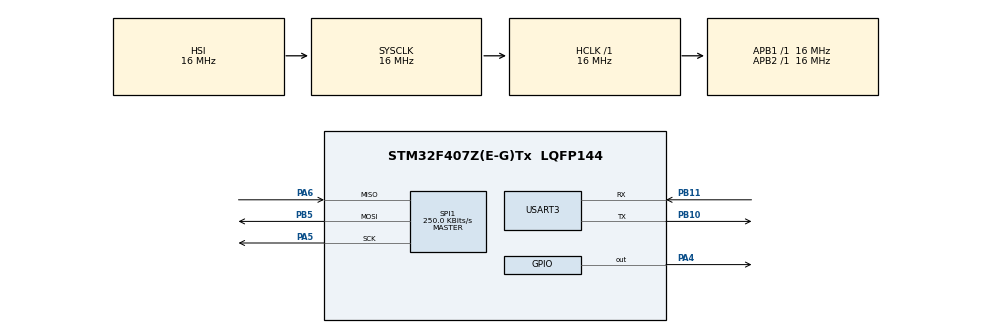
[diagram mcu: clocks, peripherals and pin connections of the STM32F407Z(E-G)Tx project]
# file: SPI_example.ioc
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FREERTOS.Tasks01=defaultTask,0,128,StartDefaultTask,Default,NULL
Mcu.Family=STM32F4
Mcu.Name=STM32F407Z(E-G)Tx
Mcu.Package=LQFP144
NVIC.PriorityGroup=NVIC_PRIORITYGROUP_4
PA4.Signal=GPIO_Output
PA5.Mode=Full_Duplex_Master
PA5.Signal=SPI1_SCK
PA6.Mode=Full_Duplex_Master
PA6.Signal=SPI1_MISO
PB10.Mode=Asynchronous
PB10.Signal=USART3_TX
PB11.Mode=Asynchronous
PB11.Signal=USART3_RX
PB5.Mode=Full_Duplex_Master
PB5.Signal=SPI1_MOSI
ProjectManager.HeapSize=0x200
ProjectManager.StackSize=0x400
ProjectManager.TargetToolchain=TrueSTUDIO
RCC.AHBFreq_Value=16000000
RCC.APB1Freq_Value=16000000
RCC.APB2Freq_Value=16000000
RCC.CortexFreq_Value=16000000
RCC.HSE_VALUE=25000000
RCC.HSI_VALUE=16000000
RCC.LSE_VALUE=32768
RCC.SYSCLKFreq_VALUE=16000000
RCC.VCOOutputFreq_Value=192000000
SPI1.BaudRatePrescaler=SPI_BAUDRATEPRESCALER_64
SPI1.CalculateBaudRate=250.0 KBits/s
SPI1.Direction=SPI_DIRECTION_2LINES
SPI1.Mode=SPI_MODE_MASTER
SPI1.VirtualType=VM_MASTER
USART3.VirtualMode=VM_ASYNC
VP_FREERTOS_VS_ENABLE.Mode=Enabled
board=custom

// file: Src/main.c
/**
  ******************************************************************************
  * @file           : main.c
  * @brief          : Main program body
  ******************************************************************************
  * This notice applies to any and all portions of this file
  * that are not between comment pairs USER CODE BEGIN and
  * USER CODE END. Other portions of this file, whether
  * inserted by the user or by software development tools
  * are owned by their respective copyright owners.
  *
  * Copyright (c) 2018 STMicroelectronics International N.V.
  * All rights reserved.
  *
  * Redistribution and use in source and binary forms, with or without
  * modification, are permitted, provided that the following conditions are met:
  *
  * 1. Redistribution of source code must retain the above copyright notice,
  *    this list of conditions and the following disclaimer.
  * 2. Redistributions in binary form must reproduce the above copyright notice,
  *    this list of conditions and the following disclaimer in the documentation
  *    and/or other materials provided with the distribution.
  * 3. Neither the name of STMicroelectronics nor the names of other
  *    contributors to this software may be used to endorse or promote products
  *    derived from this software without specific written permission.
  * 4. This software, including modifications and/or derivative works of this
  *    software, must execute solely and exclusively on microcontroller or
  *    microprocessor devices manufactured by or for STMicroelectronics.
  * 5. Redistribution and use of this software other than as permitted under
  *    this license is void and will automatically terminate your rights under
  *    this license.
  *
  * THIS SOFTWARE IS PROVIDED BY STMICROELECTRONICS AND CONTRIBUTORS "AS IS"
  * AND ANY EXPRESS, IMPLIED OR STATUTORY WARRANTIES, INCLUDING, BUT NOT
  * LIMITED TO, THE IMPLIED WARRANTIES OF MERCHANTABILITY, FITNESS FOR A
  * PARTICULAR PURPOSE AND NON-INFRINGEMENT OF THIRD PARTY INTELLECTUAL PROPERTY
  * RIGHTS ARE DISCLAIMED TO THE FULLEST EXTENT PERMITTED BY LAW. IN NO EVENT
  * SHALL STMICROELECTRONICS OR CONTRIBUTORS BE LIABLE FOR ANY DIRECT, INDIRECT,
  * INCIDENTAL, SPECIAL, EXEMPLARY, OR CONSEQUENTIAL DAMAGES (INCLUDING, BUT NOT
  * LIMITED TO, PROCUREMENT OF SUBSTITUTE GOODS OR SERVICES; LOSS OF USE, DATA,
  * OR PROFITS; OR BUSINESS INTERRUPTION) HOWEVER CAUSED AND ON ANY THEORY OF
  * LIABILITY, WHETHER IN CONTRACT, STRICT LIABILITY, OR TORT (INCLUDING
  * NEGLIGENCE OR OTHERWISE) ARISING IN ANY WAY OUT OF THE USE OF THIS SOFTWARE,
  * EVEN IF ADVISED OF THE POSSIBILITY OF SUCH DAMAGE.
  *
  ******************************************************************************
  */
#include "main.h"
#include "stm32f4xx_hal.h"
#include "cmsis_os.h"

/* USER CODE BEGIN Includes */
uint8_t spiData[2];
/* USER CODE END Includes */

SPI_HandleTypeDef hspi1;

UART_HandleTypeDef huart3;

osThreadId defaultTaskHandle;

/* USER CODE BEGIN PV */
/* Private variables ---------------------------------------------------------*/

/* USER CODE END PV */

void SystemClock_Config(void);
static void MX_GPIO_Init(void);
static void MX_SPI1_Init(void);
static void MX_USART3_UART_Init(void);
void StartDefaultTask(void const * argument);

/* USER CODE BEGIN PFP */
/* Private function prototypes -----------------------------------------------*/

/* USER CODE END PFP */

int main(void)
{

  /* MCU Configuration----------------------------------------------------------*/

  /* Reset of all peripherals, Initializes the Flash interface and the Systick. */
  HAL_Init();

  /* Configure the system clock */
  SystemClock_Config();

  /* Initialize all configured peripherals */
  MX_GPIO_Init();
  MX_SPI1_Init();
  MX_USART3_UART_Init();

  /* Create the thread(s) */
  /* definition and creation of defaultTask */
  osThreadDef(defaultTask, StartDefaultTask, osPriorityNormal, 0, 128);
  defaultTaskHandle = osThreadCreate(osThread(defaultTask), NULL);

  /* Start scheduler */
  osKernelStart();

  /* We should never get here as control is now taken by the scheduler */

  /* Infinite loop */
  /* USER CODE BEGIN WHILE */
  HAL_GPIO_WritePin(GPIOA, GPIO_PIN_4, GPIO_PIN_SET);
  while (1)
  {

  /* USER CODE END WHILE */

  }

}

void SystemClock_Config(void)
{

  RCC_OscInitTypeDef RCC_OscInitStruct;
  RCC_ClkInitTypeDef RCC_ClkInitStruct;

    /**Configure the main internal regulator output voltage
    */
  __HAL_RCC_PWR_CLK_ENABLE();

  __HAL_PWR_VOLTAGESCALING_CONFIG(PWR_REGULATOR_VOLTAGE_SCALE1);

    /**Initializes the CPU, AHB and APB busses clocks
    */
  RCC_OscInitStruct.OscillatorType = RCC_OSCILLATORTYPE_HSI;
  RCC_OscInitStruct.HSIState = RCC_HSI_ON;
  RCC_OscInitStruct.HSICalibrationValue = 16;
  RCC_OscInitStruct.PLL.PLLState = RCC_PLL_NONE;
  if (HAL_RCC_OscConfig(&RCC_OscInitStruct) != HAL_OK)
  {
    _Error_Handler(__FILE__, __LINE__);
  }

    /**Initializes the CPU, AHB and APB busses clocks
    */
  RCC_ClkInitStruct.ClockType = RCC_CLOCKTYPE_HCLK|RCC_CLOCKTYPE_SYSCLK
                              |RCC_CLOCKTYPE_PCLK1|RCC_CLOCKTYPE_PCLK2;
  RCC_ClkInitStruct.SYSCLKSource = RCC_SYSCLKSOURCE_HSI;
  RCC_ClkInitStruct.AHBCLKDivider = RCC_SYSCLK_DIV1;
  RCC_ClkInitStruct.APB1CLKDivider = RCC_HCLK_DIV1;
  RCC_ClkInitStruct.APB2CLKDivider = RCC_HCLK_DIV1;

  if (HAL_RCC_ClockConfig(&RCC_ClkInitStruct, FLASH_LATENCY_0) != HAL_OK)
  {
    _Error_Handler(__FILE__, __LINE__);
  }

    /**Configure the Systick interrupt time
    */
  HAL_SYSTICK_Config(HAL_RCC_GetHCLKFreq()/1000);

    /**Configure the Systick
    */
  HAL_SYSTICK_CLKSourceConfig(SYSTICK_CLKSOURCE_HCLK);

  /* SysTick_IRQn interrupt configuration */
  HAL_NVIC_SetPriority(SysTick_IRQn, 15, 0);
}

/* SPI1 init function */
static void MX_SPI1_Init(void)
{

  /* SPI1 parameter configuration*/
  hspi1.Instance = SPI1;
  hspi1.Init.Mode = SPI_MODE_MASTER;
  hspi1.Init.Direction = SPI_DIRECTION_2LINES;
  hspi1.Init.DataSize = SPI_DATASIZE_8BIT;
  hspi1.Init.CLKPolarity = SPI_POLARITY_LOW;
  hspi1.Init.CLKPhase = SPI_PHASE_1EDGE;
  hspi1.Init.NSS = SPI_NSS_SOFT;
  hspi1.Init.BaudRatePrescaler = SPI_BAUDRATEPRESCALER_64;
  hspi1.Init.FirstBit = SPI_FIRSTBIT_MSB;
  hspi1.Init.TIMode = SPI_TIMODE_DISABLE;
  hspi1.Init.CRCCalculation = SPI_CRCCALCULATION_DISABLE;
  hspi1.Init.CRCPolynomial = 10;
  if (HAL_SPI_Init(&hspi1) != HAL_OK)
  {
    _Error_Handler(__FILE__, __LINE__);
  }

}

/* USART3 init function */
static void MX_USART3_UART_Init(void)
{

  huart3.Instance = USART3;
  huart3.Init.BaudRate = 115200;
  huart3.Init.WordLength = UART_WORDLENGTH_8B;
  huart3.Init.StopBits = UART_STOPBITS_1;
  huart3.Init.Parity = UART_PARITY_NONE;
  huart3.Init.Mode = UART_MODE_TX_RX;
  huart3.Init.HwFlowCtl = UART_HWCONTROL_NONE;
  huart3.Init.OverSampling = UART_OVERSAMPLING_16;
  if (HAL_UART_Init(&huart3) != HAL_OK)
  {
    _Error_Handler(__FILE__, __LINE__);
  }

}

/** Configure pins as
        * Analog
        * Input
        * Output
        * EVENT_OUT
        * EXTI
*/
static void MX_GPIO_Init(void)
{

  GPIO_InitTypeDef GPIO_InitStruct;

  /* GPIO Ports Clock Enable */
  __HAL_RCC_GPIOA_CLK_ENABLE();
  __HAL_RCC_GPIOB_CLK_ENABLE();

  /*Configure GPIO pin Output Level */
  HAL_GPIO_WritePin(GPIOA, GPIO_PIN_4, GPIO_PIN_RESET);

  /*Configure GPIO pin : PA4 */
  GPIO_InitStruct.Pin = GPIO_PIN_4;
  GPIO_InitStruct.Mode = GPIO_MODE_OUTPUT_PP;
  GPIO_InitStruct.Pull = GPIO_NOPULL;
  GPIO_InitStruct.Speed = GPIO_SPEED_FREQ_LOW;
  HAL_GPIO_Init(GPIOA, &GPIO_InitStruct);

}

/* StartDefaultTask function */
void StartDefaultTask(void const * argument)
{
	//This thread read every second the direction 0xd0 of the BMP280 sensor.
	//That sensor contains the chip ID

	//Almost with this Hall it's necessary to do like a first fail reading when you
	//initialize the sensor, the it works properly
	spiData[0]=0xD0 ; //
	HAL_GPIO_WritePin(GPIOA, GPIO_PIN_4, GPIO_PIN_RESET);//Chip Select Pin set at low level
	HAL_SPI_Transmit(&hspi1,spiData,1,10);//Transmit the register dir that you want to read
	HAL_SPI_Receive(&hspi1,&spiData[1],1,10);//Then receive from the sensor the data
	HAL_GPIO_WritePin(GPIOA, GPIO_PIN_4, GPIO_PIN_SET);// Chipe Select Pin set at high level

	for(;;)
	{
		HAL_GPIO_WritePin(GPIOA, GPIO_PIN_4, GPIO_PIN_RESET);
		HAL_SPI_Transmit(&hspi1,spiData,1,10);
		HAL_SPI_Receive(&hspi1,&spiData[1],1,10);
		HAL_GPIO_WritePin(GPIOA, GPIO_PIN_4, GPIO_PIN_SET);
		printf(" Return 0x%02X \r\n",spiData[1]);
		osDelay(1000);
	}

}

void _Error_Handler(char *file, int line)
{
  while(1)
  {
  }
}

/************************ (C) COPYRIGHT STMicroelectronics *****END OF FILE****/
